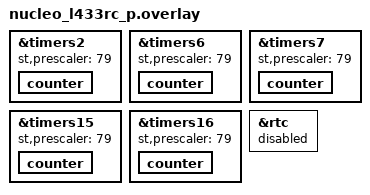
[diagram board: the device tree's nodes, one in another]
&timers2 {
	st,prescaler = <79>;
	counter {
		status = "okay";
	};
};

&timers6 {
	st,prescaler = <79>;
	counter {
		status = "okay";
	};
};

&timers7 {
	st,prescaler = <79>;
	counter {
		status = "okay";
	};
};

&timers15 {
	st,prescaler = <79>;
	counter {
		status = "okay";
	};
};

&timers16 {
	st,prescaler = <79>;
	counter {
		status = "okay";
	};
};

&rtc {
	status = "disabled";
};
